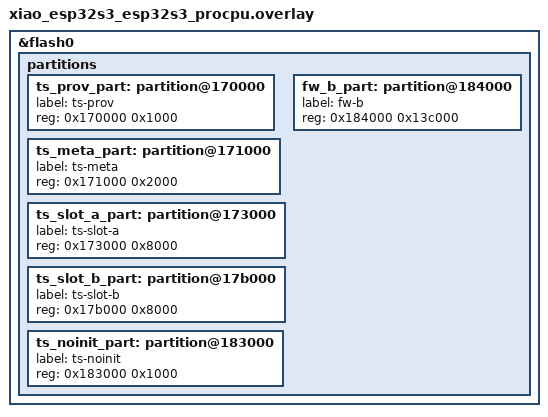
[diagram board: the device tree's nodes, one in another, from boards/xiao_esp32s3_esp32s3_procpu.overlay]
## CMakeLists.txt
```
# SPDX-License-Identifier: Apache-2.0
cmake_minimum_required(VERSION 3.20.0)
find_package(Zephyr REQUIRED HINTS $ENV{ZEPHYR_BASE})
project(tessera_persistbench)

target_sources(app PRIVATE src/main.c)
```

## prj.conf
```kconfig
# SPDX-License-Identifier: Apache-2.0
# persistbench（板级五）：prov/APP/meta flash 持久化验证。
# 首启 = 烧录会话（TS_TEST prov 注入通道〔合同 10：写通道仅烧录期/测试构建〕
# + 分步安装链 + activate）→ 暖复位；此后每次复位 = 全部状态出自 flash。
CONFIG_PRINTK=y
CONFIG_TS_CORE=y
CONFIG_TS_SAFETY=y
CONFIG_TS_APP_WAMR=y
CONFIG_TS_TEST=y
# 本基准无网面（板级四已测）：关 ts-net，避免 linkmon 无传输时按合同 3
# 将通道压入 linkloss 态（真机已观测该行为正确生效——留痕报告）。
CONFIG_TS_NET=n
CONFIG_FLASH=y
CONFIG_FLASH_MAP=y
CONFIG_TS_STORE_FLASH=y
CONFIG_REBOOT=y
# 主线程降优先级（boardbench 同款：APP 线程 10 优先投递，校验线程轮询不饿死）
CONFIG_MAIN_THREAD_PRIORITY=15
```

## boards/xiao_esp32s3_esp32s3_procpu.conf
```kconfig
# 板级内存片段（DEC-23/27 过渡值，PSRAM 挂接前）
CONFIG_TS_STORE_SLOT_SIZE=32768
CONFIG_TS_APP_THREAD_STACK=16384
# 4.5 复验批：verify 链（tweetnacl）在 4096 main 栈实测挂死（P4 教训 31⑤
# 同型——4.5 调用帧深于 4.4）；8192 实测定值。
CONFIG_MAIN_STACK_SIZE=8192
```

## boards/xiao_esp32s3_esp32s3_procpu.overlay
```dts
/*
 * 板级五：ts-store flash 分区。carved 自 espressif 4M AMP 默认布局的空闲
 * slot1 区（0x170000..0x2c0000，1344KB）：boot/sys/slot0/appcpu/lpcore/storage
 * 原样保留（esptool 偏移零变化）；slot1 删除并以 ts-store 五分区 + fw-b
 * 预留（DEC-23 固件双 slot 语义）替代。分区 4KB 对齐 = esp32s3 擦除块。
 * 尺寸耦合：slot = CONFIG_TS_STORE_SLOT_SIZE（本板 conf = 32768；part.c
 * BUILD_ASSERT 把关）。
 */
/delete-node/ &slot1_partition;

&flash0 {
	partitions {
		ts_prov_part: partition@170000 {
			label = "ts-prov";
			reg = <0x170000 0x1000>;
		};
		ts_meta_part: partition@171000 {
			label = "ts-meta";
			reg = <0x171000 0x2000>;
		};
		ts_slot_a_part: partition@173000 {
			label = "ts-slot-a";
			reg = <0x173000 0x8000>;
		};
		ts_slot_b_part: partition@17b000 {
			label = "ts-slot-b";
			reg = <0x17b000 0x8000>;
		};
		ts_noinit_part: partition@183000 {
			label = "ts-noinit";
			reg = <0x183000 0x1000>;
		};
		/* fw-b：未来 MCUmgr 固件第二 slot 预留（DEC-23；V1 未接线） */
		fw_b_part: partition@184000 {
			label = "fw-b";
			reg = <0x184000 0x13c000>;
		};
	};
};
```

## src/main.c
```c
/* SPDX-License-Identifier: Apache-2.0 */
/*
 * persistbench（板级五）：prov/APP/meta flash 持久化验证（docs/board-persist.md）。
 * 流程：
 *   首启（prov 缺失）= 烧录会话：PB1 prov 注入（TS_TEST 通道）→ PB2 分步
 *   安装链（stage_begin/chunk/verify/activate——与 sys/app-* 网络命令同一
 *   内部链）→ 暖复位；
 *   此后每次复位：PB3 全框架自举（prov/meta/slot 全部出自 flash）→
 *   PB5 APP 自举运行 + 写路径全链验证 → PB PASS。
 */
#include <string.h>
#include <zephyr/kernel.h>
#include <zephyr/sys/reboot.h>
#include <ts/appmgr.h>
#include <ts/core.h>
#include <ts/hal.h>
#include <ts/safety.h>
#include <ts/store.h>
#include <ts/tsap.h>
#include "../../../module/tessera/src/net/internal.h" /* ts_cbor_* 构造助手 */
#include "persistbench_pkg.h" /* TSAP v2 包（gen_p4b_pkg.py 机械生成，测试根签名） */

/* ---- sim 通道（框架.app 同款：唯一写路径 → driver_dispatch → sim 记录）-- */

static const ts_out_ch_t pb_ch = {
	.uid = "pb0", .kind = TS_CH_GPIO,
	.poweron = {.b = false}, .linkloss = {.b = false}, .fault = {.b = false},
};
static const ts_hal_dev_desc_t pb_dev = {.uid = "pb0", .kind = TS_DEV_GPIO_OUT};

static bool pb_gpio(void)
{
	ts_out_value_t v;

	if (ts_safety_readback("pb0", &v) != TS_OK) {
		return false;
	}
	return v.b;
}

static bool pb_wait_gpio(bool want)
{
	for (int i = 0; i < 300; i++) {
		if (pb_gpio() == want) {
			return true;
		}
		k_msleep(10);
	}
	return false;
}

/* ---- prov CBOR（schema v1 定稿键序，DEC-30⑤；定长确定性编码）------------- */

#define CB_MAX 256

struct cb {
	uint8_t b[CB_MAX];
	uint32_t n;
};

static void cb_u8(struct cb *c, uint8_t v)
{
	c->b[c->n++] = v;
}

static void cb_hdr(struct cb *c, uint8_t mt, uint32_t val)
{
	if (val < 0x18) {
		cb_u8(c, (uint8_t)(mt | val));
	} else if (val <= 0xFF) {
		cb_u8(c, (uint8_t)(mt | 0x18));
		cb_u8(c, (uint8_t)val);
	} else {
		cb_u8(c, (uint8_t)(mt | 0x19));
		cb_u8(c, (uint8_t)(val >> 8));
		cb_u8(c, (uint8_t)val);
	}
}

static void cb_tstr(struct cb *c, const char *s)
{
	cb_hdr(c, 0x60, strlen(s));
	for (size_t i = 0; i < strlen(s); i++) {
		cb_u8(c, (uint8_t)s[i]);
	}
}

static size_t build_prov(struct cb *c)
{
	memset(c, 0, sizeof(*c));
	cb_hdr(c, 0xA0, 9);
	cb_tstr(c, "v");
	cb_hdr(c, 0x00, 1);
	cb_tstr(c, "node_id");
	cb_tstr(c, "pb-dev");
	cb_tstr(c, "cube_id");
	cb_tstr(c, "cube-pb");
	cb_tstr(c, "routers");
	cb_hdr(c, 0x80, 1);
	cb_tstr(c, "tcp/192.168.2.90:9955");
	cb_tstr(c, "pk0");
	cb_hdr(c, 0x40, 32);
	for (int i = 0; i < 32; i++) {
		cb_u8(c, 0x00);
	}
	cb_tstr(c, "pk1");
	cb_hdr(c, 0x40, 32);
	for (int i = 0; i < 32; i++) {
		cb_u8(c, 0x00);
	}
	cb_tstr(c, "cred");
	cb_tstr(c, "");
	cb_tstr(c, "pwr_ma");
	cb_hdr(c, 0x00, 500);
	cb_tstr(c, "estop");
	cb_hdr(c, 0x00, 1);
	return c->n;
}

/* ---- TSAP 容器（manifest canonical 七键 + 夹具 wasm + COSE 结构尾）-------- */

/* ---- 复位后验证线程（ts_core_boot 不返回，验证并发于框架运行期）---------- */

static int pb_perm_seen;

static void pb_on_perm(const ts_evt_t *e, void *u)
{
	ARG_UNUSED(e);
	ARG_UNUSED(u);
	pb_perm_seen++;
}

/* 链路声明（部署侧）：本基准 TS_NET=n（无网面），boot 步骤 2 poweron_init
 * 将通道压回 SAFE_POWERON 后无人驱动链路——正常部署由 linkmon 在传输
 * 确立后 set_link(true)（板级四实证）。此处 BOOT_DONE 后由 glue 声明，
 * 通道迁移 ACTIVE，此后 APP 写入可达（app_init 期写入落在 SAFE 态被拒
 * = 合同 1/3 冷启动语义，init_res=-4 为预期值）。 */
static void pb_on_boot_done(const ts_evt_t *e, void *u)
{
	ARG_UNUSED(e);
	ARG_UNUSED(u);
	ts_safety_set_link(true);
	printk("PB4 boot done -> link up (glue, no-host bench)\n");
}

static void pb_verify(void *p1, void *p2, void *p3)
{
	ARG_UNUSED(p1);
	ARG_UNUSED(p2);
	ARG_UNUSED(p3);
	(void)ts_evt_subscribe(TS_EVT_PERM_DENIED, pb_on_perm, NULL);
	for (int i = 0; i < 600 && !ts_appmgr_app_running(); i++) {
		k_msleep(20);
	}
	if (!ts_appmgr_app_running()) {
		printk("PB FAIL app not running after boot\n");
		return;
	}
	ts_app_info_t info;

	ts_appmgr_get_info(&info);
	printk("PB5 app active: id=%s ver=%s slot=%u\n",
	       info.app_id, info.app_ver, info.active_slot);
	/* 诊断：init_res=-4（SAFE_POWERON 写拒绝）= 冷启动预期（见上）；此后
	 * evt 驱动写验证 ACTIVE 态全链。 */
	struct ts_app_rt_stats st;

	ts_appmgr_app_stats(&st);
	printk("PB5 diag: init_res=%d evt_seen=%u health_fails=%u perm_seen=%d\n",
	       (int)st.init_res, st.evt_seen, st.health_fails, pb_perm_seen);
	if (ts_appmgr_app_evt(1) != TS_OK || !pb_wait_gpio(true)) {
		printk("PB FAIL app_evt(1) write\n");
		return;
	}
	printk("PB5 app_evt(1) -> gpio=1 (flash slot -> boot 装载 -> wasm 全链)\n");
	if (ts_appmgr_app_evt(0) == TS_OK && pb_wait_gpio(false)) {
		printk("PB5 app_evt(0) -> gpio=0\n");
	} else {
		printk("PB FAIL app_evt(0)\n");
		return;
	}
	printk("PB PASS prov+meta+slot persisted across reset\n");
	for (;;) {
		k_msleep(5000);
		printk("PB alive t=%u\n", (unsigned)k_uptime_get_32());
	}
}
K_THREAD_DEFINE(pb_verify_tid, 2048, pb_verify, NULL, NULL, NULL, 12, 0, 1000);

int main(void)
{
	printk("PB0 persistbench\n");

	ts_res_t lr = ts_store_prov_load();

	if (lr != TS_OK) {
		/* 首启 = 烧录会话（prov 缺失；合同 10 写通道 = 烧录期/测试构建注入） */
		printk("PB1 first boot: prov absent (rc=%d) -> provision session\n", (int)lr);
		struct cb c;

		if (ts_store_prov_write_test(c.b, (uint32_t)build_prov(&c)) != TS_OK ||
		    ts_store_prov_load() != TS_OK) {
			printk("PB FAIL prov\n");
			return 1;
		}
		printk("PB1 prov burned: node=%s cube=%s\n",
		       ts_store_prov()->node_id, ts_store_prov()->cube_id);

		const uint8_t *pkg = persistbench_pkg;
		size_t total = sizeof(persistbench_pkg);
		uint8_t slot = 0;
		uint32_t hw = 0;
		const uint8_t root_key[32] = {0}; /* TEST：prov 根钥缺省（结构级验签） */

		if (total == 0) {
			printk("PB FAIL install total=0\n");
			return 1;
		}
		/* 分步报码（P4 批同型）：失败面逐级可见。4.5 复验批教训：verify
		 * 链挂死在 4096 main 栈溢出（帧深于 4.4——板 conf 已定 8192）。 */
		ts_res_t sr = ts_appmgr_stage_begin((uint32_t)total, &slot);

		if (sr != TS_OK) {
			printk("PB FAIL install begin r=%d\n", (int)sr);
			return 1;
		}
		ts_res_t cr = ts_appmgr_stage_chunk(0, pkg, (uint32_t)total, &hw);

		if (cr != TS_OK) {
			printk("PB FAIL install chunk r=%d\n", (int)cr);
			return 1;
		}
		ts_res_t vr = ts_appmgr_stage_verify(root_key, NULL, NULL, NULL);

		if (vr != TS_OK) {
			printk("PB FAIL install verify r=%d\n", (int)vr);
			return 1;
		}
		ts_app_info_t info;

		if (ts_appmgr_stage_activate(&info) != TS_OK) {
			printk("PB FAIL activate\n");
			return 1;
		}
		printk("PB2 app staged: slot=%u total=%u hw=%u -> warm reset\n",
		       slot, (unsigned)total, hw);
		sys_reboot(SYS_REBOOT_WARM);
	}

	printk("PB3 boot: prov from flash node=%s\n", ts_store_prov()->node_id);
	if (ts_hal_register_dev(&pb_dev) != TS_OK ||
	    ts_safety_register_channel(&pb_ch) != TS_OK) {
		printk("PB FAIL channel\n");
		return 1;
	}
	ts_safety_set_link(true);
	/* BOOT_DONE 订阅须在 boot 前完成（事件发布早于校验线程启动） */
	(void)ts_evt_subscribe(TS_EVT_BOOT_DONE, pb_on_boot_done, NULL);
	/* 全框架自举（步骤 8 = slot 装载）；不返回：成功进入主循环，
	 * 失败进 fail-safe 停喂 WDT（合同 6）。 */
	ts_core_boot();
}
```

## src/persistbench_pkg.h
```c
/* 机械生成（gen_p4b_pkg.py）——com.tessera.persist-0.1.0.tsap，936B（TSAP v2 + 测试根签名；wasm = app/appw/native_app.wasm） */
static const uint8_t persistbench_pkg[936] = {
	0x54, 0x53, 0x41, 0x50, 0x00, 0x02, 0x00, 0x00, 0x00, 0x78, 0x00, 0x00,
	0x01, 0x1e, 0x00, 0x01, 0x3f, 0xc7, 0x69, 0xf5, 0x90, 0xd1, 0xbc, 0xee,
	0xe9, 0x10, 0xcd, 0x89, 0x39, 0xa4, 0x10, 0xa7, 0xbf, 0x90, 0xf9, 0xb1,
	0xe5, 0xa6, 0xfb, 0x09, 0x5c, 0x8c, 0x08, 0x2b, 0xb1, 0x65, 0x84, 0xeb,
	0xa7, 0x64, 0x63, 0x61, 0x70, 0x73, 0x81, 0x6e, 0x67, 0x70, 0x69, 0x6f,
	0x3a, 0x77, 0x72, 0x69, 0x74, 0x65, 0x3a, 0x30, 0x2d, 0x33, 0x66, 0x61,
	0x70, 0x70, 0x5f, 0x69, 0x64, 0x73, 0x63, 0x6f, 0x6d, 0x2e, 0x74, 0x65,
	0x73, 0x73, 0x65, 0x72, 0x61, 0x2e, 0x70, 0x65, 0x72, 0x73, 0x69, 0x73,
	0x74, 0x67, 0x61, 0x70, 0x70, 0x5f, 0x76, 0x65, 0x72, 0x65, 0x30, 0x2e,
	0x31, 0x2e, 0x30, 0x67, 0x65, 0x78, 0x70, 0x6f, 0x72, 0x74, 0x73, 0x81,
	0x6b, 0x68, 0x65, 0x61, 0x6c, 0x74, 0x68, 0x5f, 0x70, 0x69, 0x6e, 0x67,
	0x67, 0x68, 0x65, 0x61, 0x70, 0x5f, 0x6b, 0x62, 0x08, 0x68, 0x73, 0x74,
	0x61, 0x63, 0x6b, 0x5f, 0x6b, 0x62, 0x04, 0x6a, 0x6d, 0x69, 0x6e, 0x5f,
	0x66, 0x77, 0x5f, 0x76, 0x65, 0x72, 0x65, 0x30, 0x2e, 0x30, 0x2e, 0x31,
	0x00, 0x61, 0x73, 0x6d, 0x01, 0x00, 0x00, 0x00, 0x01, 0x11, 0x03, 0x60,
	0x03, 0x7f, 0x7f, 0x7f, 0x01, 0x7f, 0x60, 0x01, 0x7f, 0x01, 0x7f, 0x60,
	0x00, 0x01, 0x7f, 0x02, 0x15, 0x01, 0x03, 0x65, 0x6e, 0x76, 0x0d, 0x74,
	0x73, 0x5f, 0x67, 0x70, 0x69, 0x6f, 0x5f, 0x77, 0x72, 0x69, 0x74, 0x65,
	0x00, 0x00, 0x03, 0x06, 0x05, 0x01, 0x01, 0x02, 0x02, 0x02, 0x04, 0x05,
	0x01, 0x70, 0x01, 0x01, 0x01, 0x05, 0x03, 0x01, 0x00, 0x02, 0x06, 0x08,
	0x01, 0x7f, 0x01, 0x41, 0x90, 0x88, 0x04, 0x0b, 0x07, 0x47, 0x06, 0x06,
	0x6d, 0x65, 0x6d, 0x6f, 0x72, 0x79, 0x02, 0x00, 0x08, 0x61, 0x70, 0x70,
	0x5f, 0x69, 0x6e, 0x69, 0x74, 0x00, 0x01, 0x07, 0x61, 0x70, 0x70, 0x5f,
	0x65, 0x76, 0x74, 0x00, 0x02, 0x08, 0x61, 0x70, 0x70, 0x5f, 0x74, 0x69,
	0x63, 0x6b, 0x00, 0x03, 0x0b, 0x68, 0x65, 0x61, 0x6c, 0x74, 0x68, 0x5f,
	0x70, 0x69, 0x6e, 0x67, 0x00, 0x04, 0x0c, 0x67, 0x65, 0x74, 0x5f, 0x6c,
	0x61, 0x73, 0x74, 0x5f, 0x65, 0x76, 0x74, 0x00, 0x05, 0x0a, 0x76, 0x05,
	0x19, 0x00, 0x41, 0x00, 0x20, 0x00, 0x36, 0x02, 0x84, 0x88, 0x80, 0x80,
	0x00, 0x20, 0x00, 0x41, 0x00, 0x41, 0x01, 0x10, 0x80, 0x80, 0x80, 0x80,
	0x00, 0x0b, 0x3d, 0x00, 0x02, 0x40, 0x20, 0x00, 0x41, 0x80, 0x02, 0x71,
	0x45, 0x0d, 0x00, 0x41, 0x00, 0x41, 0x01, 0x36, 0x02, 0x88, 0x88, 0x80,
	0x80, 0x00, 0x41, 0x00, 0x0f, 0x0b, 0x41, 0x00, 0x20, 0x00, 0x36, 0x02,
	0x80, 0x88, 0x80, 0x80, 0x00, 0x41, 0x00, 0x28, 0x02, 0x84, 0x88, 0x80,
	0x80, 0x00, 0x41, 0x00, 0x20, 0x00, 0x41, 0x01, 0x71, 0x10, 0x80, 0x80,
	0x80, 0x80, 0x00, 0x0b, 0x04, 0x00, 0x41, 0x00, 0x0b, 0x0b, 0x00, 0x41,
	0x00, 0x28, 0x02, 0x88, 0x88, 0x80, 0x80, 0x00, 0x0b, 0x0b, 0x00, 0x41,
	0x00, 0x28, 0x02, 0x80, 0x88, 0x80, 0x80, 0x00, 0x0b, 0x0b, 0x0b, 0x01,
	0x00, 0x41, 0x80, 0x08, 0x0b, 0x04, 0xff, 0xff, 0xff, 0xff, 0xd2, 0x84,
	0x43, 0xa1, 0x01, 0x27, 0xa0, 0x59, 0x01, 0x96, 0xa7, 0x64, 0x63, 0x61,
	0x70, 0x73, 0x81, 0x6e, 0x67, 0x70, 0x69, 0x6f, 0x3a, 0x77, 0x72, 0x69,
	0x74, 0x65, 0x3a, 0x30, 0x2d, 0x33, 0x66, 0x61, 0x70, 0x70, 0x5f, 0x69,
	0x64, 0x73, 0x63, 0x6f, 0x6d, 0x2e, 0x74, 0x65, 0x73, 0x73, 0x65, 0x72,
	0x61, 0x2e, 0x70, 0x65, 0x72, 0x73, 0x69, 0x73, 0x74, 0x67, 0x61, 0x70,
	0x70, 0x5f, 0x76, 0x65, 0x72, 0x65, 0x30, 0x2e, 0x31, 0x2e, 0x30, 0x67,
	0x65, 0x78, 0x70, 0x6f, 0x72, 0x74, 0x73, 0x81, 0x6b, 0x68, 0x65, 0x61,
	0x6c, 0x74, 0x68, 0x5f, 0x70, 0x69, 0x6e, 0x67, 0x67, 0x68, 0x65, 0x61,
	0x70, 0x5f, 0x6b, 0x62, 0x08, 0x68, 0x73, 0x74, 0x61, 0x63, 0x6b, 0x5f,
	0x6b, 0x62, 0x04, 0x6a, 0x6d, 0x69, 0x6e, 0x5f, 0x66, 0x77, 0x5f, 0x76,
	0x65, 0x72, 0x65, 0x30, 0x2e, 0x30, 0x2e, 0x31, 0x00, 0x61, 0x73, 0x6d,
	0x01, 0x00, 0x00, 0x00, 0x01, 0x11, 0x03, 0x60, 0x03, 0x7f, 0x7f, 0x7f,
	0x01, 0x7f, 0x60, 0x01, 0x7f, 0x01, 0x7f, 0x60, 0x00, 0x01, 0x7f, 0x02,
	0x15, 0x01, 0x03, 0x65, 0x6e, 0x76, 0x0d, 0x74, 0x73, 0x5f, 0x67, 0x70,
	0x69, 0x6f, 0x5f, 0x77, 0x72, 0x69, 0x74, 0x65, 0x00, 0x00, 0x03, 0x06,
	0x05, 0x01, 0x01, 0x02, 0x02, 0x02, 0x04, 0x05, 0x01, 0x70, 0x01, 0x01,
	0x01, 0x05, 0x03, 0x01, 0x00, 0x02, 0x06, 0x08, 0x01, 0x7f, 0x01, 0x41,
	0x90, 0x88, 0x04, 0x0b, 0x07, 0x47, 0x06, 0x06, 0x6d, 0x65, 0x6d, 0x6f,
	0x72, 0x79, 0x02, 0x00, 0x08, 0x61, 0x70, 0x70, 0x5f, 0x69, 0x6e, 0x69,
	0x74, 0x00, 0x01, 0x07, 0x61, 0x70, 0x70, 0x5f, 0x65, 0x76, 0x74, 0x00,
	0x02, 0x08, 0x61, 0x70, 0x70, 0x5f, 0x74, 0x69, 0x63, 0x6b, 0x00, 0x03,
	0x0b, 0x68, 0x65, 0x61, 0x6c, 0x74, 0x68, 0x5f, 0x70, 0x69, 0x6e, 0x67,
	0x00, 0x04, 0x0c, 0x67, 0x65, 0x74, 0x5f, 0x6c, 0x61, 0x73, 0x74, 0x5f,
	0x65, 0x76, 0x74, 0x00, 0x05, 0x0a, 0x76, 0x05, 0x19, 0x00, 0x41, 0x00,
	0x20, 0x00, 0x36, 0x02, 0x84, 0x88, 0x80, 0x80, 0x00, 0x20, 0x00, 0x41,
	0x00, 0x41, 0x01, 0x10, 0x80, 0x80, 0x80, 0x80, 0x00, 0x0b, 0x3d, 0x00,
	0x02, 0x40, 0x20, 0x00, 0x41, 0x80, 0x02, 0x71, 0x45, 0x0d, 0x00, 0x41,
	0x00, 0x41, 0x01, 0x36, 0x02, 0x88, 0x88, 0x80, 0x80, 0x00, 0x41, 0x00,
	0x0f, 0x0b, 0x41, 0x00, 0x20, 0x00, 0x36, 0x02, 0x80, 0x88, 0x80, 0x80,
	0x00, 0x41, 0x00, 0x28, 0x02, 0x84, 0x88, 0x80, 0x80, 0x00, 0x41, 0x00,
	0x20, 0x00, 0x41, 0x01, 0x71, 0x10, 0x80, 0x80, 0x80, 0x80, 0x00, 0x0b,
	0x04, 0x00, 0x41, 0x00, 0x0b, 0x0b, 0x00, 0x41, 0x00, 0x28, 0x02, 0x88,
	0x88, 0x80, 0x80, 0x00, 0x0b, 0x0b, 0x00, 0x41, 0x00, 0x28, 0x02, 0x80,
	0x88, 0x80, 0x80, 0x00, 0x0b, 0x0b, 0x0b, 0x01, 0x00, 0x41, 0x80, 0x08,
	0x0b, 0x04, 0xff, 0xff, 0xff, 0xff, 0x58, 0x40, 0x62, 0xda, 0x5e, 0x80,
	0x69, 0xd9, 0xcf, 0x55, 0x70, 0xa4, 0x46, 0x2d, 0xc1, 0xc2, 0xd8, 0x70,
	0xb2, 0x21, 0x76, 0x00, 0xe9, 0x1a, 0xdb, 0xaf, 0xa5, 0x62, 0xcf, 0x3f,
	0x71, 0xc2, 0xf0, 0xa9, 0xce, 0xce, 0xa4, 0x8e, 0x96, 0x14, 0x6e, 0x3f,
	0xf8, 0xf4, 0x2a, 0x9a, 0x8c, 0x9b, 0x05, 0xcb, 0x5a, 0x2c, 0x7c, 0x62,
	0xe8, 0x04, 0x0a, 0x42, 0x58, 0x99, 0x8f, 0x1e, 0xc6, 0xe2, 0x62, 0x03,
};
```
